# iostr735 register map
Registers from a debugger description file.
Registers are 16-bit, access not given, no defined reset value unless marked. A register's access mark holds for its fields unless they carry their own. Addresses are absolute; registers are grouped by the start of their names; lines under a group give offsets from that group; [hi:lo] are bit positions; {n}, {i} and the like mark numbered series; 'fields as' and 'values as' point back to an identical list; <NAME> marks a mode.

## CMU
0xFFFFF600 CMU_RCCTL
  [3:0] RCCTL
0xFFFFF604 CMU_FDISP
  [11:0] FD
0xFFFFF608 CMU_FRH
  [11:0] FH
0xFFFFF60C CMU_FRL
  [11:0] FL
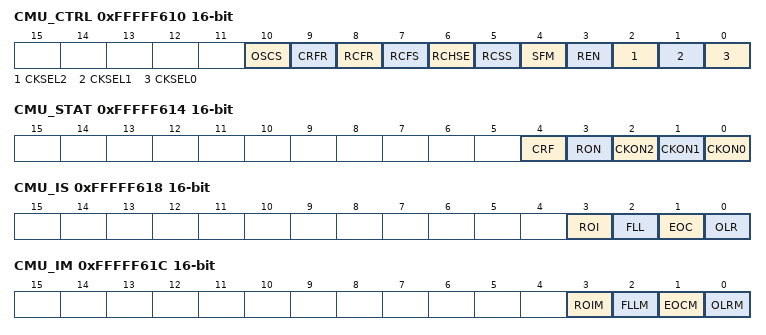
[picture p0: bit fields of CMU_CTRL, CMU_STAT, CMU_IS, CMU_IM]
0xFFFFF610 CMU_CTRL
  [10] OSCS, [9] CRFR, [8] RCFR, [7] RCFS, [6] RCHSE, [5] RCSS, [4] SFM, [3] REN, [2] CKSEL2, [1] CKSEL1, [0] CKSEL0
0xFFFFF614 CMU_STAT
  [4] CRF, [3] RON, [2] CKON2, [1] CKON1, [0] CKON0
0xFFFFF618 CMU_IS
  [3] ROI, [2] FLL, [1] EOC, [0] OLR
0xFFFFF61C CMU_IM
  [3] ROIM, [2] FLLM, [1] EOCM, [0] OLRM
0xFFFFF620 CMU_EOCV
  [7:0] EOCV
0xFFFFF624 CMU_WE

## PRCCU
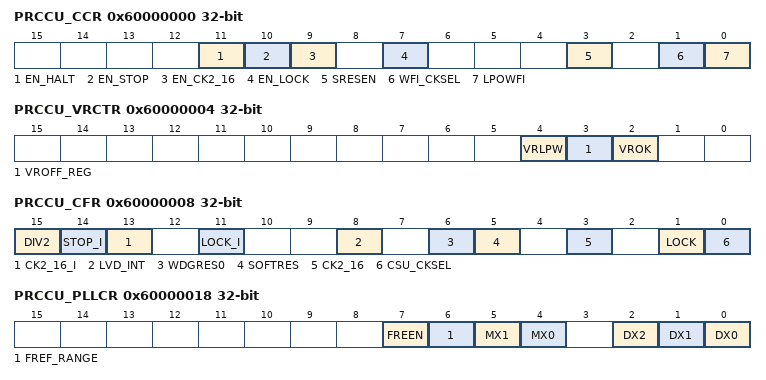
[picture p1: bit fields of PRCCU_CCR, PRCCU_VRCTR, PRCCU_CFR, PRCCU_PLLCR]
0x60000000 PRCCU_CCR 32-bit
  [11] EN_HALT, [10] EN_STOP, [9] EN_CK2_16, [7] EN_LOCK, [3] SRESEN, [1] WFI_CKSEL, [0] LPOWFI
0x60000004 PRCCU_VRCTR 32-bit
  [4] VRLPW, [3] VROFF_REG, [2] VROK
0x60000008 PRCCU_CFR 32-bit
  [15] DIV2, [14] STOP_I, [13] CK2_16_I, [11] LOCK_I, [8] LVD_INT, [6] WDGRES0, [5] SOFTRES, [3] CK2_16, [1] LOCK, [0] CSU_CKSEL
0x60000018 PRCCU_PLLCR 32-bit
  [7] FREEN, [6] FREF_RANGE, [5] MX1, [4] MX0, [2] DX2, [1] DX1, [0] DX0
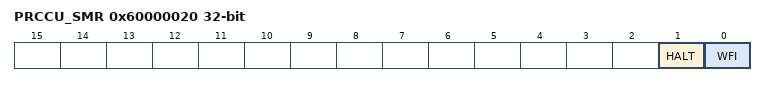
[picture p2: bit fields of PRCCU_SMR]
0x60000020 PRCCU_SMR 32-bit
  [1] HALT, [0] WFI
0x60000028 PRCCU_RTCPR 32-bit
  [3:0] RTCP

## CFG
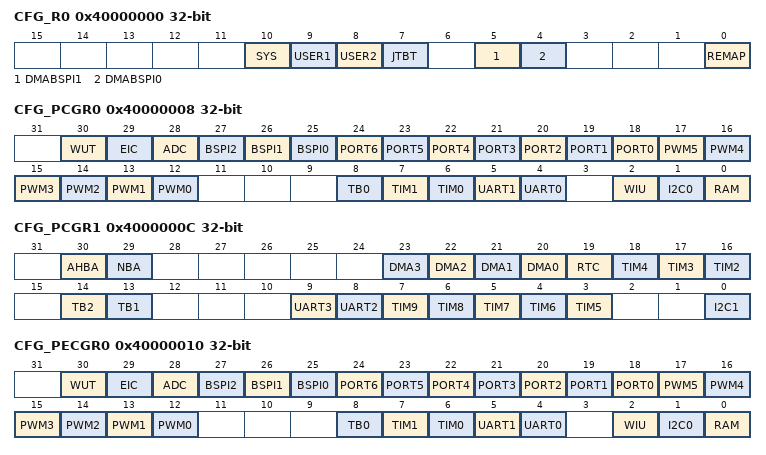
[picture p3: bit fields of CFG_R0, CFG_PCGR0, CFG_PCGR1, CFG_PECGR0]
0x40000000 CFG_R0 32-bit
  [10] SYS, [9] USER1, [8] USER2, [7] JTBT, [5] DMABSPI1, [4] DMABSPI0, [0] REMAP
0x40000004 CFG_EITE0 32-bit
  [15:0] EITE0
0x40000008 CFG_PCGR0 32-bit
  [30] WUT, [29] EIC, [28] ADC, [27] BSPI2, [26] BSPI1, [25] BSPI0, [n+18] PORT{n} (n=0..6), [n+12] PWM{n} (n=0..5), [8] TB0, [7] TIM1, [6] TIM0, [5] UART1, [4] UART0, [2] WIU, [1] I2C0, [0] RAM
0x4000000C CFG_PCGR1 32-bit
  [30] AHBA, [29] NBA, [n+20] DMA{n} (n=0..3), [19] RTC, [18] TIM4, [17] TIM3, [16] TIM2, [14] TB2, [13] TB1, [9] UART3, [8] UART2, [n-2] TIM{n} (n=5..9), [0] I2C1
0x40000010 CFG_PECGR0 32-bit
  fields as CFG_PCGR0
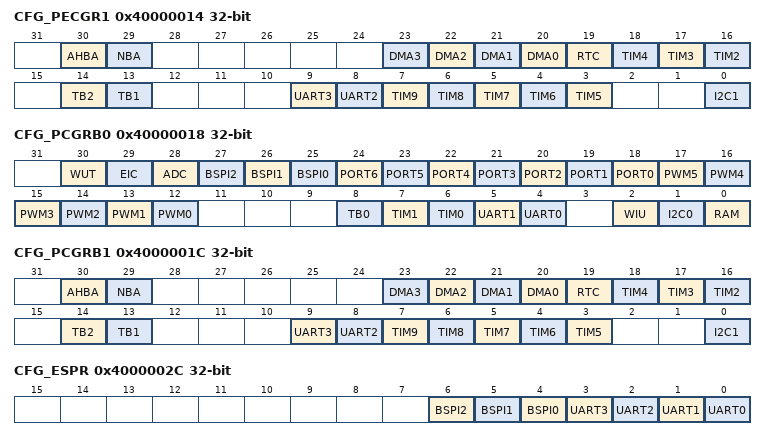
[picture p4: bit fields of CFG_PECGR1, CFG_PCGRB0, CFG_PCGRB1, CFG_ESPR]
0x40000014 CFG_PECGR1 32-bit
  fields as CFG_PCGR1
0x40000018 CFG_PCGRB0 32-bit
  fields as CFG_PCGR0
0x4000001C CFG_PCGRB1 32-bit
  fields as CFG_PCGR1
0x40000020 CFG_TIMSR 32-bit
  [9:0] TIMECKS
0x40000024 CFG_EITE1 32-bit
  [15:0] EITE1
0x40000028 CFG_EITE2 32-bit
  [15:0] EITE2
0x4000002C CFG_ESPR 32-bit
  [6] BSPI2, [5] BSPI1, [4] BSPI0, [n] UART{n} (n=0..3)
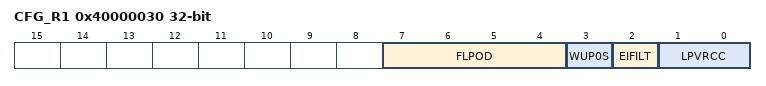
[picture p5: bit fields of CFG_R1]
0x40000030 CFG_R1 32-bit
  [7:4] FLPOD, [3] WUP0S, [2] EIFILT, [1:0] LPVRCC
0x40000034 CFG_DIDR 32-bit

## GPIOPORT0
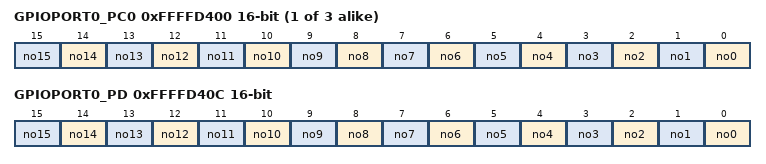
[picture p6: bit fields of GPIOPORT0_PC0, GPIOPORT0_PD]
{0xFFFFD400+4i} GPIOPORT0_PC{i} (i=0..2)
  [n] no{n} (n=0..15)
0xFFFFD40C GPIOPORT0_PD
  [n] no{n} (n=0..15)

## GPIOPORT1
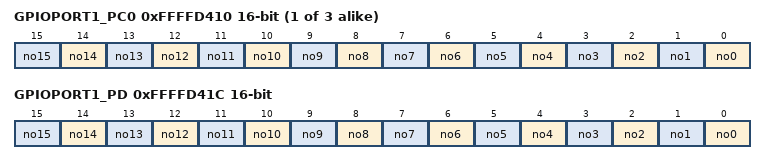
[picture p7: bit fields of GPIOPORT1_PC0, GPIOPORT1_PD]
{0xFFFFD410+4i} GPIOPORT1_PC{i} (i=0..2)
  [n] no{n} (n=0..15)
0xFFFFD41C GPIOPORT1_PD
  [n] no{n} (n=0..15)

## GPIOPORT2
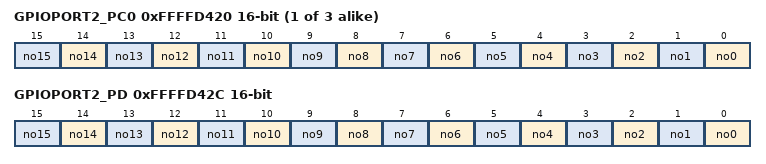
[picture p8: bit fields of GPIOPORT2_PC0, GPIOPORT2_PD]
{0xFFFFD420+4i} GPIOPORT2_PC{i} (i=0..2)
  [n] no{n} (n=0..15)
0xFFFFD42C GPIOPORT2_PD
  [n] no{n} (n=0..15)

## GPIOPORT3
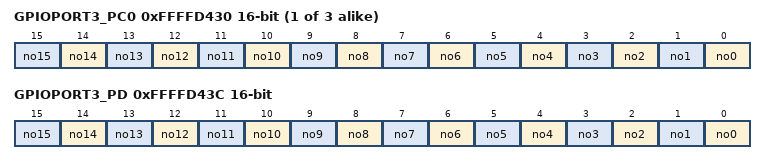
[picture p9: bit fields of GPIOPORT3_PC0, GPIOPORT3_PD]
{0xFFFFD430+4i} GPIOPORT3_PC{i} (i=0..2)
  [n] no{n} (n=0..15)
0xFFFFD43C GPIOPORT3_PD
  [n] no{n} (n=0..15)
